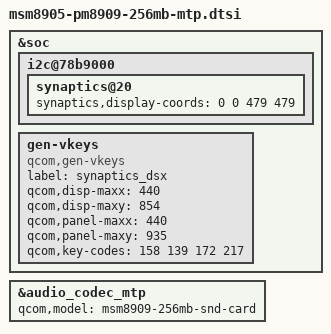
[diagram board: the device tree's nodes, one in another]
/*
 * Copyright (c) 2017, The Linux Foundation. All rights reserved.
 *
 * This program is free software; you can redistribute it and/or modify
 * it under the terms of the GNU General Public License version 2 and
 * only version 2 as published by the Free Software Foundation.
 *
 * This program is distributed in the hope that it will be useful,
 * but WITHOUT ANY WARRANTY; without even the implied warranty of
 * MERCHANTABILITY or FITNESS FOR A PARTICULAR PURPOSE.  See the
 * GNU General Public License for more details.
 */

#include "msm8905-pm8909-mtp.dtsi"
#include "msm8905-256mb-memory.dtsi"

&soc {
	i2c@78b9000 { /* BLSP1 QUP5 */
		synaptics@20 {
			synaptics,display-coords = <0 0 479 479>;
		};
	};

	gen-vkeys {
		compatible = "qcom,gen-vkeys";
		label = "synaptics_dsx";
		qcom,disp-maxx = <440>;
		qcom,disp-maxy = <854>;
		qcom,panel-maxx = <440>;
		qcom,panel-maxy = <935>;
		qcom,key-codes = <158 139 172 217>;
	};
};

&audio_codec_mtp {
	qcom,model = "msm8909-256mb-snd-card";
};
